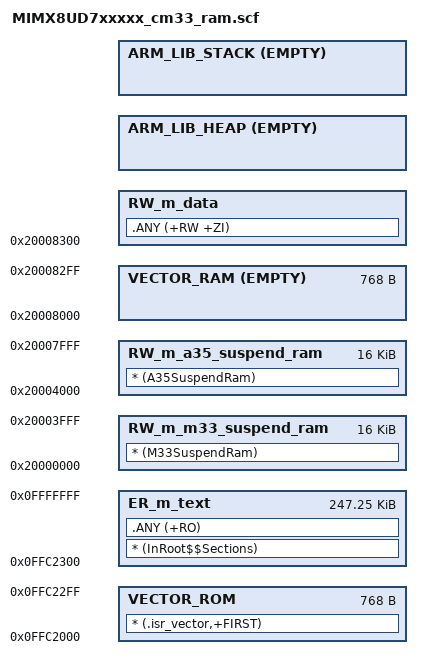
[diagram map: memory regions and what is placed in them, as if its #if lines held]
#!armclang --target=arm-arm-none-eabi -mcpu=cortex-m4 -E -x c
/*
** ###################################################################
**     Processors:          MIMX8UD7CVP08_cm33
**                          MIMX8UD7DVK08_cm33
**                          MIMX8UD7DVP08_cm33
**
**     Compiler:            Keil ARM C/C++ Compiler
**     Reference manual:    IMX8ULPRM, Rev. D, December. 2022
**     Version:             rev. 5.0, 2023-04-27
**     Build:               b230927
**
**     Abstract:
**         Linker file for the Keil ARM C/C++ Compiler
**
**     Copyright 2016 Freescale Semiconductor, Inc.
**     Copyright 2016-2023 NXP
**     SPDX-License-Identifier: BSD-3-Clause
**
**     http:                 www.nxp.com
**     mail:                 support@nxp.com
**
** ###################################################################
*/

/* Memory region from [0x0FFC0000-0x0FFC1FFF] is reserved for ROM code */

#if (defined(__ram_vector_table__))
  #define __ram_vector_table_size__    0x00000300
#else
  #define __ram_vector_table_size__    0x00000000
#endif

#define m_interrupts_start             0x0FFC2000
#define m_interrupts_size              0x00000300

#define m_text_start                   0x0FFC2300
#define m_text_size                    0x0003DD00

#define m_m33_suspend_ram_start        0x20000000
#define m_m33_suspend_ram_size         0x00004000

#define m_a35_suspend_ram_start        0x20004000
#define m_a35_suspend_ram_size         0x00004000

#define m_interrupts_ram_start         0x20008000
#define m_interrupts_ram_size          __ram_vector_table_size__

#define m_data_start                   (m_interrupts_ram_start + m_interrupts_ram_size)
#define m_data_size                    (0x00080000 - m_interrupts_ram_size)

/* Sizes */
#if (defined(__stack_size__))
  #define Stack_Size                   __stack_size__
#else
  #define Stack_Size                   0x0400
#endif

#if (defined(__heap_size__))
  #define Heap_Size                    __heap_size__
#else
  #define Heap_Size                    0x0400
#endif

LR_m_text m_interrupts_start m_text_start+m_text_size-m_interrupts_start { ; load region size_region
  VECTOR_ROM m_interrupts_start m_interrupts_size { ; load address = execution address
    * (.isr_vector,+FIRST)
  }
  ER_m_text m_text_start m_text_size { ; load address = execution address
    * (InRoot$$Sections)
    .ANY (+RO)
  }
  RW_m_m33_suspend_ram m_m33_suspend_ram_start m_m33_suspend_ram_size { ; RW data
    * (M33SuspendRam)
  }
  RW_m_a35_suspend_ram m_a35_suspend_ram_start m_a35_suspend_ram_size { ; RW data
    * (A35SuspendRam)
  }

#if (defined(__ram_vector_table__))
  VECTOR_RAM m_interrupts_ram_start EMPTY m_interrupts_ram_size {
  }
#else
  VECTOR_RAM m_interrupts_start EMPTY 0 {
  }
#endif
  RW_m_data m_data_start m_data_size-Stack_Size-Heap_Size { ; RW data
    .ANY (+RW +ZI)
  }
  ARM_LIB_HEAP +0 EMPTY Heap_Size {    ; Heap region growing up
  }
  ARM_LIB_STACK m_data_start+m_data_size EMPTY -Stack_Size { ; Stack region growing down
  }
}
